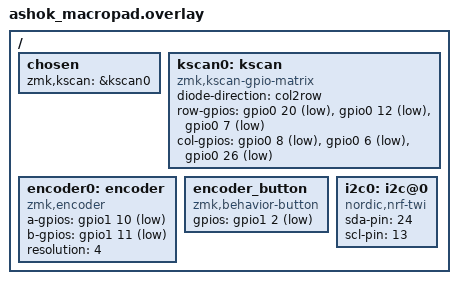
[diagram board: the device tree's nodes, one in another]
/*
 * Ashok Macropad Overlay
 */

 #include <dt-bindings/zmk/matrix_transform.h>

 #include <zephyr/dt-bindings/gpio/gpio.h>
 
 #include <layouts/default/3x3.dtsi>  /* optional layout include if you have one */
 
 / {
     chosen {
         zmk,kscan = &kscan0;
         // You can define a physical layout here if you have one (optional)
     };
 
     kscan0: kscan {
         compatible = "zmk,kscan-gpio-matrix";
         diode-direction = "col2row";  // Assuming col2row — change if you're wired row2col
 
         row-gpios = 
             <&gpio0 20 (GPIO_ACTIVE_LOW | GPIO_PULL_DOWN)>,
             <&gpio0 12 (GPIO_ACTIVE_LOW | GPIO_PULL_DOWN)>,
             <&gpio0 7  (GPIO_ACTIVE_LOW | GPIO_PULL_DOWN)>;
 
         col-gpios = 
             <&gpio0 8  (GPIO_ACTIVE_LOW | GPIO_PULL_DOWN)>,
             <&gpio0 6  (GPIO_ACTIVE_LOW | GPIO_PULL_DOWN)>,
             <&gpio0 26 (GPIO_ACTIVE_LOW | GPIO_PULL_DOWN)>;
     };
 
     encoder0: encoder {
         compatible = "zmk,encoder";
         a-gpios = <&gpio1 10 (GPIO_ACTIVE_LOW | GPIO_PULL_UP)>;
         b-gpios = <&gpio1 11 (GPIO_ACTIVE_LOW | GPIO_PULL_UP)>;
         resolution = <4>;
     };
 
     encoder_button: encoder_button {
         compatible = "zmk,behavior-button";
         gpios = <&gpio1 2 (GPIO_ACTIVE_LOW | GPIO_PULL_UP)>;
     };
 
     i2c0: i2c@0 {
         compatible = "nordic,nrf-twi";
         status = "okay";
         sda-pin = <24>;
         scl-pin = <13>;
     };
 };
 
